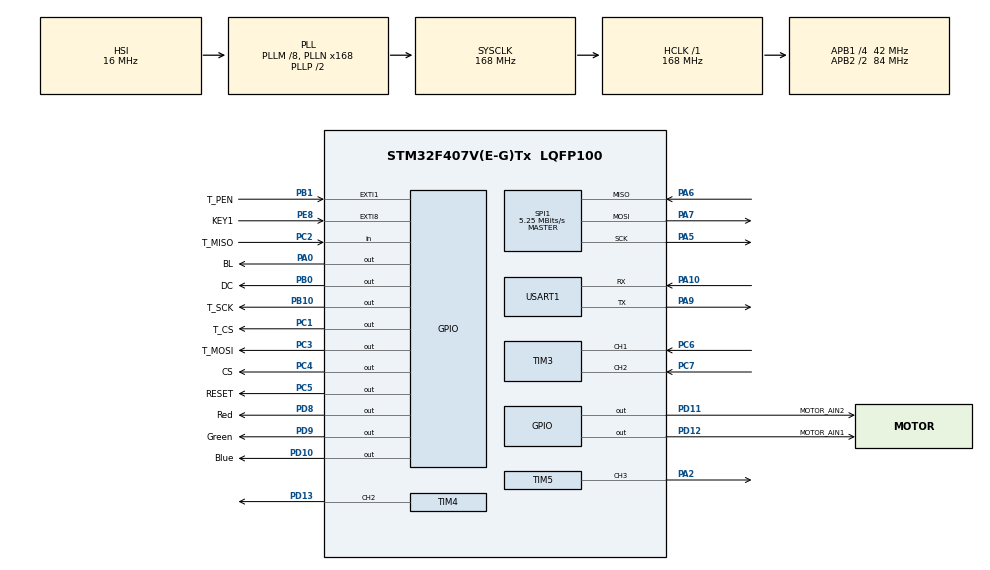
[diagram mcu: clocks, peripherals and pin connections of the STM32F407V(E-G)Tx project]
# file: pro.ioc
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Dma.Request0=SPI1_TX
Dma.Request1=USART1_RX
Dma.SPI1_TX.0.Direction=DMA_MEMORY_TO_PERIPH
Dma.SPI1_TX.0.FIFOMode=DMA_FIFOMODE_DISABLE
Dma.SPI1_TX.0.Instance=DMA2_Stream3
Dma.SPI1_TX.0.MemDataAlignment=DMA_MDATAALIGN_HALFWORD
Dma.SPI1_TX.0.MemInc=DMA_MINC_ENABLE
Dma.SPI1_TX.0.Mode=DMA_NORMAL
Dma.SPI1_TX.0.PeriphDataAlignment=DMA_PDATAALIGN_HALFWORD
Dma.SPI1_TX.0.PeriphInc=DMA_PINC_DISABLE
Dma.SPI1_TX.0.Priority=DMA_PRIORITY_VERY_HIGH
Dma.USART1_RX.1.Direction=DMA_PERIPH_TO_MEMORY
Dma.USART1_RX.1.FIFOMode=DMA_FIFOMODE_DISABLE
Dma.USART1_RX.1.Instance=DMA2_Stream2
Dma.USART1_RX.1.MemDataAlignment=DMA_MDATAALIGN_BYTE
Dma.USART1_RX.1.MemInc=DMA_MINC_ENABLE
Dma.USART1_RX.1.Mode=DMA_NORMAL
Dma.USART1_RX.1.PeriphDataAlignment=DMA_PDATAALIGN_BYTE
Dma.USART1_RX.1.PeriphInc=DMA_PINC_DISABLE
Dma.USART1_RX.1.Priority=DMA_PRIORITY_LOW
FREERTOS.Tasks01=defaultTask,24,128,StartDefaultTask,Default,NULL,Dynamic,NULL,NULL
FREERTOS.configCHECK_FOR_STACK_OVERFLOW=2
FREERTOS.configUSE_TICK_HOOK=1
Mcu.Family=STM32F4
Mcu.Name=STM32F407V(E-G)Tx
Mcu.Package=LQFP100
NVIC.DMA2_Stream2_IRQn=true\:5\:0\:false\:false\:true\:true\:false\:true\:true
NVIC.DMA2_Stream3_IRQn=true\:5\:0\:false\:false\:true\:true\:false\:true\:true
NVIC.EXTI1_IRQn=true\:5\:0\:false\:false\:true\:true\:true\:true\:true
NVIC.EXTI9_5_IRQn=true\:5\:0\:false\:false\:true\:true\:true\:true\:true
NVIC.PriorityGroup=NVIC_PRIORITYGROUP_4
NVIC.SPI1_IRQn=true\:5\:0\:false\:false\:true\:true\:true\:true\:true
NVIC.TIM1_UP_TIM10_IRQn=true\:15\:0\:false\:false\:true\:false\:false\:true\:true
NVIC.TimeBase=TIM1_UP_TIM10_IRQn
NVIC.TimeBaseIP=TIM1
NVIC.USART1_IRQn=true\:5\:0\:false\:false\:true\:true\:true\:true\:true
PA0-WKUP.GPIO_Label=BL
PA0-WKUP.GPIO_Speed=GPIO_SPEED_FREQ_HIGH
PA0-WKUP.Signal=GPIO_Output
PA10.Mode=Asynchronous
PA10.Signal=USART1_RX
PA13.Mode=Serial_Wire
PA13.Signal=SYS_JTMS-SWDIO
PA14.Mode=Serial_Wire
PA14.Signal=SYS_JTCK-SWCLK
PA2.Signal=S_TIM5_CH3
PA5.Mode=Full_Duplex_Master
PA5.Signal=SPI1_SCK
PA6.Mode=Full_Duplex_Master
PA6.Signal=SPI1_MISO
PA7.Mode=Full_Duplex_Master
PA7.Signal=SPI1_MOSI
PA9.Mode=Asynchronous
PA9.Signal=USART1_TX
PB0.GPIO_Label=DC
PB0.GPIO_Speed=GPIO_SPEED_FREQ_HIGH
PB0.Signal=GPIO_Output
PB1.GPIO_Label=T_PEN
PB1.GPIO_PuPd=GPIO_PULLUP
PB1.Signal=GPXTI1
PB10.GPIO_Label=T_SCK
PB10.GPIO_Speed=GPIO_SPEED_FREQ_HIGH
PB10.Signal=GPIO_Output
PC1.GPIO_Label=T_CS
PC1.GPIO_Speed=GPIO_SPEED_FREQ_HIGH
PC1.Signal=GPIO_Output
PC14-OSC32_IN.Mode=LSE-External-Oscillator
PC14-OSC32_IN.Signal=RCC_OSC32_IN
PC15-OSC32_OUT.Mode=LSE-External-Oscillator
PC15-OSC32_OUT.Signal=RCC_OSC32_OUT
PC2.GPIO_Label=T_MISO
PC2.GPIO_Mode=GPIO_MODE_INPUT
PC2.GPIO_PuPd=GPIO_PULLUP
PC2.Signal=GPIO_Input
PC3.GPIO_Label=T_MOSI
PC3.Signal=GPIO_Output
PC4.GPIO_Label=CS
PC4.Signal=GPIO_Output
PC5.GPIO_Label=RESET
PC5.Signal=GPIO_Output
PC6.Signal=S_TIM3_CH1
PC7.Signal=S_TIM3_CH2
PD10.GPIO_Label=Blue
PD10.Signal=GPIO_Output
PD11.GPIO_Label=MOTOR_AIN2
PD11.Signal=GPIO_Output
PD12.GPIO_Label=MOTOR_AIN1
PD12.Signal=GPIO_Output
PD13.Signal=S_TIM4_CH2
PD8.GPIO_Label=Red
PD8.Signal=GPIO_Output
PD9.GPIO_Label=Green
PD9.Signal=GPIO_Output
PE8.GPIO_Label=KEY1
PE8.GPIO_PuPd=GPIO_PULLUP
PE8.Signal=GPXTI8
PH0-OSC_IN.Mode=HSE-External-Oscillator
PH0-OSC_IN.Signal=RCC_OSC_IN
PH1-OSC_OUT.Mode=HSE-External-Oscillator
PH1-OSC_OUT.Signal=RCC_OSC_OUT
ProjectManager.HeapSize=0x200
ProjectManager.StackSize=0x400
ProjectManager.TargetToolchain=MDK-ARM V5.32
RCC.48MHZClocksFreq_Value=84000000
RCC.AHBFreq_Value=168000000
RCC.APB1CLKDivider=RCC_HCLK_DIV4
RCC.APB1Freq_Value=42000000
RCC.APB1TimFreq_Value=84000000
RCC.APB2CLKDivider=RCC_HCLK_DIV2
RCC.APB2Freq_Value=84000000
RCC.APB2TimFreq_Value=168000000
RCC.CortexFreq_Value=168000000
RCC.HCLKFreq_Value=168000000
RCC.HSE_VALUE=25000000
RCC.HSI_VALUE=16000000
RCC.PLLM=8
RCC.PLLN=168
RCC.SYSCLKFreq_VALUE=168000000
RCC.SYSCLKSource=RCC_SYSCLKSOURCE_PLLCLK
RCC.VCOOutputFreq_Value=336000000
RTC.Date=11
RTC.Hours=6
RTC.Minutes=6
RTC.Month=RTC_MONTH_JUNE
RTC.Seconds=6
RTC.WeekDay=RTC_WEEKDAY_THURSDAY
RTC.Year=26
SH.S_TIM3_CH1.0=TIM3_CH1,Encoder_Interface
SH.S_TIM3_CH2.0=TIM3_CH2,Encoder_Interface
SH.S_TIM4_CH2.0=TIM4_CH2,PWM Generation2 CH2
SH.S_TIM5_CH3.0=TIM5_CH3,PWM Generation3 CH3
SPI1.BaudRatePrescaler=SPI_BAUDRATEPRESCALER_16
SPI1.CalculateBaudRate=5.25 MBits/s
SPI1.Direction=SPI_DIRECTION_2LINES
SPI1.Mode=SPI_MODE_MASTER
SPI1.VirtualType=VM_MASTER
TIM3.EncoderMode=TIM_ENCODERMODE_TI12
TIM3.IC1Filter=15
TIM3.IC2Filter=15
TIM4.Channel-PWM\ Generation2\ CH2=TIM_CHANNEL_2
TIM4.Period=99
TIM4.Prescaler=83
TIM5.Channel-PWM\ Generation3\ CH3=TIM_CHANNEL_3
TIM5.Prescaler=167
USART1.VirtualMode=VM_ASYNC
VP_FREERTOS_VS_CMSIS_V2.Mode=CMSIS_V2
VP_RTC_VS_RTC_Activate.Mode=RTC_Enabled
VP_RTC_VS_RTC_Calendar.Mode=RTC_Calendar
VP_SYS_VS_tim1.Mode=TIM1
VP_TIM4_VS_ClockSourceINT.Mode=Internal
VP_TIM5_VS_ClockSourceINT.Mode=Internal
board=custom

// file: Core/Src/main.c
/* USER CODE BEGIN Header */
/**
  ******************************************************************************
  * @file           : main.c
  * @brief          : Main program body
  ******************************************************************************
  * @attention
  *
  * Copyright (c) 2026 STMicroelectronics.
  * All rights reserved.
  *
  * This software is licensed under terms that can be found in the LICENSE file
  * in the root directory of this software component.
  * If no LICENSE file comes with this software, it is provided AS-IS.
  *
  ******************************************************************************
  */
/* USER CODE END Header */
#include "main.h"
#include "cmsis_os.h"
#include "dma.h"
#include "rtc.h"
#include "spi.h"
#include "tim.h"
#include "usart.h"
#include "gpio.h"

/* USER CODE BEGIN Includes */
#include "myspi.h"
/* USER CODE END Includes */

void SystemClock_Config(void);
void MX_FREERTOS_Init(void);

int main(void)
{

  /* MCU Configuration--------------------------------------------------------*/

  /* Reset of all peripherals, Initializes the Flash interface and the Systick. */
  HAL_Init();

  /* Configure the system clock */
  SystemClock_Config();

  /* Initialize all configured peripherals */
  MX_GPIO_Init();
  MX_DMA_Init();
  MX_SPI1_Init();
  MX_USART1_UART_Init();
  MX_RTC_Init();
  MX_TIM3_Init();
  MX_TIM4_Init();
  MX_TIM5_Init();

  /* Init scheduler */
  osKernelInitialize();  /* Call init function for freertos objects (in cmsis_os2.c) */
  MX_FREERTOS_Init();

  /* Start scheduler */
  osKernelStart();

  /* We should never get here as control is now taken by the scheduler */

  /* Infinite loop */
  /* USER CODE BEGIN WHILE */
//  LCD_Init();
//  LCD_Set_Light(10);
//  LCD_Fill(0,0,480,240,WHITE);
  while (1)
  {
    /* USER CODE END WHILE */

  }
}

void SystemClock_Config(void)
{
  RCC_OscInitTypeDef RCC_OscInitStruct = {0};
  RCC_ClkInitTypeDef RCC_ClkInitStruct = {0};

  /** Configure the main internal regulator output voltage
  */
  __HAL_RCC_PWR_CLK_ENABLE();
  __HAL_PWR_VOLTAGESCALING_CONFIG(PWR_REGULATOR_VOLTAGE_SCALE1);

  /** Initializes the RCC Oscillators according to the specified parameters
  * in the RCC_OscInitTypeDef structure.
  */
  RCC_OscInitStruct.OscillatorType = RCC_OSCILLATORTYPE_HSI|RCC_OSCILLATORTYPE_LSI;
  RCC_OscInitStruct.HSIState = RCC_HSI_ON;
  RCC_OscInitStruct.HSICalibrationValue = RCC_HSICALIBRATION_DEFAULT;
  RCC_OscInitStruct.LSIState = RCC_LSI_ON;
  RCC_OscInitStruct.PLL.PLLState = RCC_PLL_ON;
  RCC_OscInitStruct.PLL.PLLSource = RCC_PLLSOURCE_HSI;
  RCC_OscInitStruct.PLL.PLLM = 8;
  RCC_OscInitStruct.PLL.PLLN = 168;
  RCC_OscInitStruct.PLL.PLLP = RCC_PLLP_DIV2;
  RCC_OscInitStruct.PLL.PLLQ = 4;
  if (HAL_RCC_OscConfig(&RCC_OscInitStruct) != HAL_OK)
  {
    Error_Handler();
  }

  /** Initializes the CPU, AHB and APB buses clocks
  */
  RCC_ClkInitStruct.ClockType = RCC_CLOCKTYPE_HCLK|RCC_CLOCKTYPE_SYSCLK
                              |RCC_CLOCKTYPE_PCLK1|RCC_CLOCKTYPE_PCLK2;
  RCC_ClkInitStruct.SYSCLKSource = RCC_SYSCLKSOURCE_PLLCLK;
  RCC_ClkInitStruct.AHBCLKDivider = RCC_SYSCLK_DIV1;
  RCC_ClkInitStruct.APB1CLKDivider = RCC_HCLK_DIV4;
  RCC_ClkInitStruct.APB2CLKDivider = RCC_HCLK_DIV2;

  if (HAL_RCC_ClockConfig(&RCC_ClkInitStruct, FLASH_LATENCY_5) != HAL_OK)
  {
    Error_Handler();
  }
}

void HAL_TIM_PeriodElapsedCallback(TIM_HandleTypeDef *htim)
{
  if (htim->Instance == TIM1)
  {
    HAL_IncTick();
  }
}

void Error_Handler(void)
{
  __disable_irq();
  while (1)
  {
  }
}

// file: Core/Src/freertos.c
/* USER CODE BEGIN Header */
/**
  ******************************************************************************
  * File Name          : freertos.c
  * Description        : Code for freertos applications
  ******************************************************************************
  * @attention
  *
  * Copyright (c) 2026 STMicroelectronics.
  * All rights reserved.
  *
  * This software is licensed under terms that can be found in the LICENSE file
  * in the root directory of this software component.
  * If no LICENSE file comes with this software, it is provided AS-IS.
  *
  ******************************************************************************
  */
/* USER CODE END Header */

#include "FreeRTOS.h"
#include "task.h"
#include "main.h"
#include "cmsis_os.h"

/* USER CODE BEGIN Includes */
#include "lcd.h"
/* USER CODE END Includes */

/* Definitions for defaultTask */
osThreadId_t defaultTaskHandle;
const osThreadAttr_t defaultTask_attributes = {
  .name = "defaultTask",
  .stack_size = 128 * 4,
  .priority = (osPriority_t) osPriorityNormal,
};
/* Definitions for LCD_Task */
osThreadId_t LCD_TaskHandle;
const osThreadAttr_t LCD_Task_attributes = {
  .name = "LCD_Task",
  .stack_size = 128 * 4,
  .priority = (osPriority_t) osPriorityNormal,
};

void StartDefaultTask(void *argument);
void task(void *argument);

void MX_FREERTOS_Init(void); /* (MISRA C 2004 rule 8.1) */

void MX_FREERTOS_Init(void) {

  /* Create the thread(s) */
  /* creation of defaultTask */
  defaultTaskHandle = osThreadNew(StartDefaultTask, NULL, &defaultTask_attributes);

  /* creation of LCD_Task */
  LCD_TaskHandle = osThreadNew(task, NULL, &LCD_Task_attributes);

}

void StartDefaultTask(void *argument)
{
  /* USER CODE BEGIN StartDefaultTask */
  LCD_Init();
  /* Infinite loop */
  for(;;)
  {
    osDelay(1);
  }
  /* USER CODE END StartDefaultTask */
}

void task(void *argument)
{
  for(;;)
  {
    osDelay(1);
  }
}
